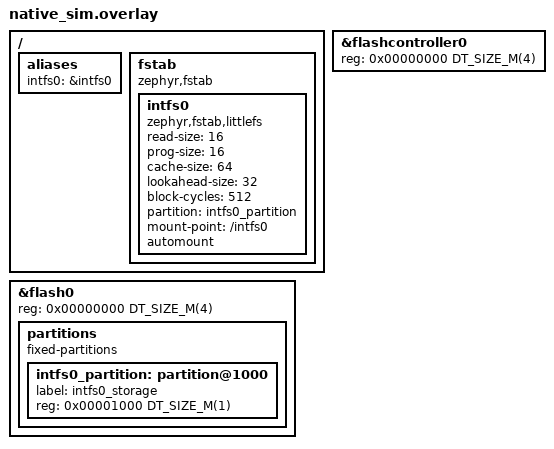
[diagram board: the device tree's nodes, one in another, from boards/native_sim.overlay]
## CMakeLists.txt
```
cmake_minimum_required(VERSION 3.20.0)

set(RT_GAUGE_TEST_SIM_FLASH ON)

# Deliberately NOT RT_GAUGE_TEST_LVGL: UiController goes through UiRendererService,
# which refuses to start without a chosen display, so this suite binds LVGL to the
# dummy display driver (see boards/native_sim.overlay) instead of running headless.
include(${CMAKE_CURRENT_SOURCE_DIR}/../../rt_gauge_test.cmake)

# Use Zephyr's build system
find_package(Zephyr REQUIRED HINTS $ENV{ZEPHYR_BASE})
project(functional_controllers)

include_directories(${APP_SRC_DIR})

set(APP_SRC_CONFIGURATION_DIR ${APP_SRC_DIR}/configuration)
file(GLOB_RECURSE APP_SRC_CONFIGURATION
  ${APP_SRC_CONFIGURATION_DIR}/*.c
  ${APP_SRC_CONFIGURATION_DIR}/*.cpp
)

set(APP_SRC_UI_DOMAIN_DIR ${APP_SRC_DIR}/domain/ui_domain)
file(GLOB_RECURSE APP_SRC_UI_DOMAIN
  ${APP_SRC_UI_DOMAIN_DIR}/*.c
  ${APP_SRC_UI_DOMAIN_DIR}/*.cpp
)

set(APP_SRC_EVENT_BUS_DIR ${APP_SRC_DIR}/event_bus)
file(GLOB_RECURSE APP_SRC_EVENT_BUS
  ${APP_SRC_EVENT_BUS_DIR}/*.c
  ${APP_SRC_EVENT_BUS_DIR}/*.cpp
)

set(APP_SRC_VIEWS_DIR ${APP_SRC_DIR}/views)
file(GLOB_RECURSE APP_SRC_VIEWS
  ${APP_SRC_VIEWS_DIR}/*.c
  ${APP_SRC_VIEWS_DIR}/*.cpp
)

# Only UiController: the other controllers pull in CAN, BLE and the sensor stack,
# none of which this suite exercises.
file(GLOB_RECURSE APP_SRC_CONTROLLERS
  ${APP_SRC_DIR}/controllers/ui_controller.cpp
)

file(GLOB_RECURSE TEST_SOURCES src/*.c src/*.cpp)

# Add all source files to the app target
target_sources(app PRIVATE
  ${APP_SRC_CONFIGURATION}
  ${APP_SRC_CONTROLLERS}
  ${APP_SRC_EVENT_BUS}
  ${APP_SRC_UI_DOMAIN}
  ${APP_SRC_VIEWS}
  ${TEST_SOURCES}
)
```

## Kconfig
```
menu "Zephyr"
source "Kconfig.zephyr"
endmenu

config EERIE_LEAP_HW_VERSION_MAJOR
	int "Hardware version major"
	range 0 255
	default 0

config EERIE_LEAP_HW_VERSION_MINOR
	int "Hardware version minor"
	range 0 255
	default 0

config EERIE_LEAP_HW_VERSION_PATCH
	int "Hardware version patch"
	range 0 65535
	default 0

config EERIE_LEAP_SW_VERSION_MAJOR
	int "Software version major"
	range 0 255
	default 0

config EERIE_LEAP_SW_VERSION_MINOR
	int "Software version minor"
	range 0 255
	default 0

config EERIE_LEAP_SW_VERSION_PATCH
	int "Software version patch"
	range 0 65535
	default 0

config EERIE_LEAP_UI_RENDERER_THREAD_STACK_SIZE
	int "UI renderer thread stack size"
	default 8192

config EERIE_LEAP_FS_SD_THREAD_STACK_SIZE
	int "SD thread stack size"
	default 2048

config EERIE_LEAP_SD_CHECK_INTERVAL_MS
	int "SD check interval ms"
	default 1000
```

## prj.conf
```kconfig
CONFIG_ZTEST=y

#HW Version
CONFIG_EERIE_LEAP_HW_VERSION_MAJOR=2
CONFIG_EERIE_LEAP_HW_VERSION_MINOR=9
CONFIG_EERIE_LEAP_HW_VERSION_PATCH=6

#SW Version
CONFIG_EERIE_LEAP_SW_VERSION_MAJOR=7
CONFIG_EERIE_LEAP_SW_VERSION_MINOR=8
CONFIG_EERIE_LEAP_SW_VERSION_PATCH=4

# Language and Compiler
CONFIG_CPP=y
CONFIG_PICOLIBC=y
CONFIG_STD_CPP23=y
CONFIG_REQUIRES_FULL_LIBCPP=y
CONFIG_CPP_EXCEPTIONS=y
CONFIG_CPP_RTTI=y

# Memory
# Without CONFIG_SHARED_MULTI_HEAP the external PMR falls back to k_malloc, and the
# demo image assets alone are ~870 KB of statically initialised pmr vectors.
# A "small only" sys_heap is capped at 256 KB and fails to init before logging is
# up, so the size mode has to be widened along with the pool.
CONFIG_SYS_HEAP_AUTO=y
CONFIG_HEAP_MEM_POOL_SIZE=4194304

# The controller and its work queues allocate their stacks at runtime.
CONFIG_THREAD_STACK_INFO=y
CONFIG_DYNAMIC_THREAD=y
CONFIG_DYNAMIC_THREAD_ALLOC=y

# C++ exception unwinding needs considerably more stack than the ztest defaults.
CONFIG_MAIN_STACK_SIZE=16384
CONFIG_ZTEST_STACK_SIZE=16384

# Logging And Debugging
CONFIG_LOG=y
# A fault during static init or LVGL setup loses deferred output.
CONFIG_LOG_MODE_IMMEDIATE=y
CONFIG_TEST_RANDOM_GENERATOR=y
CONFIG_THREAD_ANALYZER=y
CONFIG_THREAD_ANALYZER_USE_LOG=y
CONFIG_THREAD_RUNTIME_STATS=y
CONFIG_THREAD_NAME=y
CONFIG_SYS_HEAP_RUNTIME_STATS=y
CONFIG_THREAD_ANALYZER_ISR_STACK_USAGE=n

# FS Config
CONFIG_FLASH=y
CONFIG_FLASH_MAP=y
CONFIG_FILE_SYSTEM=y
CONFIG_FILE_SYSTEM_LITTLEFS=y
CONFIG_FILE_SYSTEM_MKFS=y

# CBOR
CONFIG_ZCBOR=y

# LVGL
# UiRendererService refuses to start without a chosen, ready display, so unlike the
# other LVGL suites this one lets LVGL auto-init against the dummy display driver.
CONFIG_DISPLAY=y
CONFIG_LVGL=y
CONFIG_LV_Z_MEM_POOL_SIZE=1048576
CONFIG_LV_USE_LOG=n
CONFIG_LV_USE_LABEL=y
CONFIG_LV_USE_IMAGE=y
CONFIG_LV_USE_FONT_COMPRESSED=y
CONFIG_LV_FONT_MONTSERRAT_20=y
CONFIG_LV_FONT_DEFAULT_UNSCII_16=y
# The demo assets are AL88, as on the device.
CONFIG_LV_COLOR_DEPTH_8=y
CONFIG_LV_Z_BITS_PER_PIXEL=8

CONFIG_CRC=y
CONFIG_TIMING_FUNCTIONS=y

CONFIG_EERIE_LEAP_RT_CORE=y
CONFIG_EERIE_LEAP_ASSETS=y
CONFIG_EERIE_LEAP_CONFIGURATION=y
CONFIG_EERIE_LEAP_DEVICE_TREE=y
CONFIG_EERIE_LEAP_EVENT_BUS=y
CONFIG_EERIE_LEAP_FS=y
CONFIG_EERIE_LEAP_RANDOM=y
CONFIG_EERIE_LEAP_TIME=y
CONFIG_EERIE_LEAP_LUA_SCRIPT=y
CONFIG_EERIE_LEAP_MATH_PARSER=y
```

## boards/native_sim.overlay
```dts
/ {
	aliases {
		intfs0 = &intfs0;
	};

	fstab {
		compatible = "zephyr,fstab";
		intfs0: intfs0 {
			compatible = "zephyr,fstab,littlefs";
			read-size = <16>;
			prog-size = <16>;
			cache-size = <64>;
			lookahead-size = <32>;
			block-cycles = <512>;
			partition = <&intfs0_partition>;
			mount-point = "/intfs0";
			automount;
		};
	};
};

&flashcontroller0 {
	reg = <0x00000000 DT_SIZE_M(4)>;  // 4MB flash controller
};

// HEX Flash dump can be found in the duild/flash.bin file
&flash0 {
	reg = <0x00000000 DT_SIZE_M(4)>;  // 4MB total flash

	partitions {
		compatible = "fixed-partitions";
		#address-cells = <1>;
		#size-cells = <1>;

		intfs0_partition: partition@1000 {
			label = "intfs0_storage";
			reg = <0x00001000 DT_SIZE_M(1)>;  // 0x00001000 offset, 1MB size
		};
	};
};
```

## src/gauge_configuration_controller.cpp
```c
#include <memory>
#include <zephyr/kernel.h>
#include <zephyr/ztest.h>

#include "configuration/gauge_config/gauge_config.h"
#include "configuration/services/configuration_service.h"

#include "domain/ui_domain/configuration/ui_configuration_manager.h"
#include "domain/ui_domain/models/widget_property.h"

#include "subsys/device_tree/dt_fs.h"
#include "subsys/fs/services/fs_service.h"

#include "views/widgets/indicators/horizontal_chart_indicator/horizontal_chart_indicator.h"

using namespace eerie_leap::configuration::services;
using namespace eerie_leap::subsys::device_tree;
using namespace eerie_leap::subsys::fs::services;
using namespace eerie_leap::domain::ui_domain::configuration;
using namespace eerie_leap::domain::ui_domain::models;
using namespace eerie_leap::views::widgets::indicators;

ZTEST_SUITE(ui_configuration_manager, NULL, NULL, NULL, NULL, NULL);

std::shared_ptr<UiConfiguration> ui_configuration_manager_test_SetupTestGaugeConfig() {
    auto ui_configuration = make_shared_ext<UiConfiguration>();
    ui_configuration->active_screen_index = 8;

    ScreenConfiguration screen_configuration {
        .id = 8,
        .grid = GridSettings {
            .snap_enabled = true,
            .width = 3,
            .height = 3,
            .spacing_px = 0
        },
        .widget_configurations = {
            WidgetConfiguration {
                .type = WidgetType::IndicatorArcFill,
                .id = 0,
                .position_grid = WidgetPosition {
                    .x = 0,
                    .y = 0
                },
                .size_grid = WidgetSize {
                    .width = 3,
                    .height = 3
                },
                .properties = {
                    { WidgetProperty::GetTypeName(WidgetPropertyType::MIN_VALUE), 0 },
                    { WidgetProperty::GetTypeName(WidgetPropertyType::MAX_VALUE), 100 },
                    { WidgetProperty::GetTypeName(WidgetPropertyType::SENSOR_ID), "2348664336" }
                }
            },
            WidgetConfiguration {
                .type = WidgetType::IndicatorDigital,
                .id = 1,
                .position_grid = WidgetPosition {
                    .x = 1,
                    .y = 1
                },
                .size_grid = WidgetSize {
                    .width = 1,
                    .height = 1
                },
                .properties = {
                    { WidgetProperty::GetTypeName(WidgetPropertyType::MIN_VALUE), 0 },
                    { WidgetProperty::GetTypeName(WidgetPropertyType::MAX_VALUE), 100 },
                    { WidgetProperty::GetTypeName(WidgetPropertyType::SENSOR_ID), "2348664336" }
                }
            },
            WidgetConfiguration {
                .type = WidgetType::IndicatorHorizontalChart,
                .id = 2,
                .position_grid = WidgetPosition {
                    .x = 0,
                    .y = 0
                },
                .size_grid = WidgetSize {
                    .width = 3,
                    .height = 1
                },
                .properties = {
                    { WidgetProperty::GetTypeName(WidgetPropertyType::MIN_VALUE), 0 },
                    { WidgetProperty::GetTypeName(WidgetPropertyType::MAX_VALUE), 100 },
                    { WidgetProperty::GetTypeName(WidgetPropertyType::SENSOR_ID), "2348664336" },
                    { WidgetProperty::GetTypeName(WidgetPropertyType::CHART_POINT_COUNT), 35 },
                    { WidgetProperty::GetTypeName(WidgetPropertyType::CHART_TYPE), static_cast<std::uint16_t>(HorizontalChartIndicatorType::LINE) }
                }
            }
        }
    };

    ui_configuration->screen_configurations.push_back(screen_configuration);

    return ui_configuration;
}

ZTEST(ui_configuration_manager, test_UiConfigurationManager_Save_config_successfully_saved) {
    DtFs::InitInternalFs();
    auto fs_service = std::make_shared<FsService>(DtFs::GetInternalFsMp().value());

    fs_service->Format();

    auto ui_configuration_service = std::make_shared<ConfigurationService<GaugeConfig>>("gauge_config", fs_service);
    auto ui_configuration_manager = std::make_shared<UiConfigurationManager>(ui_configuration_service);

    auto gauge_config = ui_configuration_manager_test_SetupTestGaugeConfig();
    bool result = ui_configuration_manager->Update(gauge_config);
    zassert_true(result);
}

ZTEST(ui_configuration_manager, test_UiConfigurationManager_Save_config_and_Load) {
    DtFs::InitInternalFs();
    auto fs_service = std::make_shared<FsService>(DtFs::GetInternalFsMp().value());

    fs_service->Format();

    auto ui_configuration_service = std::make_shared<ConfigurationService<GaugeConfig>>("gauge_config", fs_service);
    auto ui_configuration_manager = std::make_shared<UiConfigurationManager>(ui_configuration_service);

    auto gauge_config = ui_configuration_manager_test_SetupTestGaugeConfig();
    bool result = ui_configuration_manager->Update(gauge_config);
    zassert_true(result);

    auto saved_ui_configuration = *ui_configuration_manager->Get(true);

    zassert_equal(saved_ui_configuration.active_screen_index, gauge_config->active_screen_index);

    for (std::size_t i = 0; i < gauge_config->screen_configurations.size(); i++) {
        zassert_equal(saved_ui_configuration.screen_configurations[i].id, gauge_config->screen_configurations[i].id);
        zassert_equal(saved_ui_configuration.screen_configurations[i].grid.snap_enabled, gauge_config->screen_configurations[i].grid.snap_enabled);
        zassert_equal(saved_ui_configuration.screen_configurations[i].grid.width, gauge_config->screen_configurations[i].grid.width);
        zassert_equal(saved_ui_configuration.screen_configurations[i].grid.height, gauge_config->screen_configurations[i].grid.height);
        zassert_equal(saved_ui_configuration.screen_configurations[i].grid.spacing_px, gauge_config->screen_configurations[i].grid.spacing_px);

        for (std::size_t j = 0; j < gauge_config->screen_configurations[i].widget_configurations.size(); j++) {
            zassert_equal(saved_ui_configuration.screen_configurations[i].widget_configurations[j].type, gauge_config->screen_configurations[i].widget_configurations[j].type);
            zassert_equal(saved_ui_configuration.screen_configurations[i].widget_configurations[j].id, gauge_config->screen_configurations[i].widget_configurations[j].id);
            zassert_equal(saved_ui_configuration.screen_configurations[i].widget_configurations[j].position_grid.x, gauge_config->screen_configurations[i].widget_configurations[j].position_grid.x);
            zassert_equal(saved_ui_configuration.screen_configurations[i].widget_configurations[j].position_grid.y, gauge_config->screen_configurations[i].widget_configurations[j].position_grid.y);
            zassert_equal(saved_ui_configuration.screen_configurations[i].widget_configurations[j].size_grid.width, gauge_config->screen_configurations[i].widget_configurations[j].size_grid.width);
            zassert_equal(saved_ui_configuration.screen_configurations[i].widget_configurations[i].size_grid.height, gauge_config->screen_configurations[i].widget_configurations[i].size_grid.height);
            zassert_equal(saved_ui_configuration.screen_configurations[i].widget_configurations[i].properties.size(), gauge_config->screen_configurations[i].widget_configurations[i].properties.size());

            for (auto& property : gauge_config->screen_configurations[i].widget_configurations[j].properties) {
                zassert_true(saved_ui_configuration.screen_configurations[i].widget_configurations[j].properties[property.first] == gauge_config->screen_configurations[i].widget_configurations[j].properties[property.first]);
            }
        }
    }
}
```

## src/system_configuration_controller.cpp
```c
#include <memory>
#include <zephyr/kernel.h>
#include <zephyr/ztest.h>

#include "configuration/cbor/cbor_system_config/cbor_system_config.h"
#include "configuration/services/cbor_configuration_service.h"
#include "domain/system_domain/configuration/system_configuration_manager.h"

#include "subsys/device_tree/dt_fs.h"
#include "subsys/fs/services/fs_service.h"

using namespace eerie_leap::configuration::services;
using namespace eerie_leap::subsys::device_tree;
using namespace eerie_leap::subsys::fs::services;
using namespace eerie_leap::domain::system_domain::configuration;

ZTEST_SUITE(system_configuration_manager, NULL, NULL, NULL, NULL, NULL);

ZTEST(system_configuration_manager, test_CborSystemConfigurationManager_Save_config_successfully_saved) {
    DtFs::InitInternalFs();
    auto fs_service = std::make_shared<FsService>(DtFs::GetInternalFsMp().value());

    fs_service->Format();

    auto system_configuration_service = std::make_unique<CborConfigurationService<CborSystemConfig>>("system_config", fs_service);
    auto system_configuration_manager = std::make_shared<SystemConfigurationManager>(std::move(system_configuration_service));

    SystemConfiguration system_configuration {
        .hw_version = 23456,
        .sw_version = 87654
    };

    bool result = system_configuration_manager->Update(system_configuration);
    zassert_true(result);

    auto saved_system_configuration = *system_configuration_manager->Get(true);

    zassert_equal(saved_system_configuration.hw_version, system_configuration.hw_version);
    zassert_equal(saved_system_configuration.sw_version, system_configuration.sw_version);
}

ZTEST(system_configuration_manager, test_CborSystemConfigurationManager_Save_config_and_Load) {
    DtFs::InitInternalFs();
    auto fs_service = std::make_shared<FsService>(DtFs::GetInternalFsMp().value());

    fs_service->Format();

    auto system_configuration_service = std::make_unique<CborConfigurationService<CborSystemConfig>>("system_config", fs_service);
    auto system_configuration_manager = std::make_shared<SystemConfigurationManager>(std::move(system_configuration_service));

    SystemConfiguration system_configuration {
        .device_id = 14
    };

    bool result = system_configuration_manager->Update(system_configuration);
    zassert_true(result);

    system_configuration_service = std::make_unique<CborConfigurationService<CborSystemConfig>>("system_config", fs_service);
    system_configuration_manager = std::make_shared<SystemConfigurationManager>(std::move(system_configuration_service));

    auto saved_system_configuration = *system_configuration_manager->Get(true);

    zassert_equal(saved_system_configuration.device_id, system_configuration.device_id);
    zassert_equal(saved_system_configuration.hw_version, 0x02090006);
    zassert_equal(saved_system_configuration.sw_version, 0x07080004);
}
```

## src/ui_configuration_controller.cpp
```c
#include <memory>
#include <zephyr/kernel.h>
#include <zephyr/ztest.h>
#include <eerie_memory.hpp>

#include "configuration/cbor/cbor_ui_config/cbor_ui_config.h"
#include "configuration/services/cbor_configuration_service.h"

#include "domain/ui_domain/configuration/ui_configuration_manager.h"
#include "domain/ui_domain/models/widget_property.h"

#include "subsys/device_tree/dt_fs.h"
#include "subsys/fs/services/fs_service.h"

#include "views/widgets/indicators/horizontal_chart_indicator/horizontal_chart_indicator.h"

using namespace eerie_memory;
using namespace eerie_leap::configuration::services;
using namespace eerie_leap::subsys::device_tree;
using namespace eerie_leap::subsys::fs::services;
using namespace eerie_leap::domain::ui_domain::configuration;
using namespace eerie_leap::domain::ui_domain::models;
using namespace eerie_leap::views::widgets::indicators;

ZTEST_SUITE(ui_configuration_manager, NULL, NULL, NULL, NULL, NULL);

std::shared_ptr<UiConfiguration> ui_configuration_manager_test_SetupTestUiConfiguration() {
    auto ui_configuration = make_shared_pmr<UiConfiguration>(Mrm::GetDefaultPmr());
    ui_configuration->active_screen_group_id = 3;

    auto screen_configuration = make_shared_pmr<ScreenConfiguration>(Mrm::GetDefaultPmr());
    screen_configuration->id = 8;
    screen_configuration->group_id = 3;
    screen_configuration->type = ScreenType::Gauge;
    screen_configuration->z_index = -2;
    screen_configuration->is_visible = true;

    screen_configuration->grid.snap_enabled = true;
    screen_configuration->grid.width = 3;
    screen_configuration->grid.height = 3;
    screen_configuration->grid.spacing_px = 0;

    // First widget
    auto widget1 = make_shared_pmr<WidgetConfiguration>(Mrm::GetDefaultPmr());
    widget1->type = WidgetType::IndicatorArcFill;
    widget1->id = 0;
    widget1->position_grid.x = 0;
    widget1->position_grid.y = 0;
    widget1->size_grid.width = 3;
    widget1->size_grid.height = 3;
    widget1->z_index = -1;
    widget1->properties[WidgetProperty::GetTypeName(WidgetPropertyType::MIN_VALUE)] = 0;
    widget1->properties[WidgetProperty::GetTypeName(WidgetPropertyType::MAX_VALUE)] = 100;
    widget1->properties[WidgetProperty::GetTypeName(WidgetPropertyType::SENSOR_ID)] = "2348664336";
    screen_configuration->AddWidget(std::move(widget1));

    // Second widget
    auto widget2 = make_shared_pmr<WidgetConfiguration>(Mrm::GetDefaultPmr());
    widget2->type = WidgetType::IndicatorDigital;
    widget2->id = 1;
    widget2->position_grid.x = 1;
    widget2->position_grid.y = 1;
    widget2->size_grid.width = 1;
    widget2->size_grid.height = 1;
    widget2->is_visible = false;
    widget2->properties[WidgetProperty::GetTypeName(WidgetPropertyType::MIN_VALUE)] = 0;
    widget2->properties[WidgetProperty::GetTypeName(WidgetPropertyType::MAX_VALUE)] = 100;
    widget2->properties[WidgetProperty::GetTypeName(WidgetPropertyType::SENSOR_ID)] = "2348664336";
    screen_configuration->AddWidget(std::move(widget2));

    // Third widget
    auto widget3 = make_shared_pmr<WidgetConfiguration>(Mrm::GetDefaultPmr());
    widget3->type = WidgetType::IndicatorHorizontalChart;
    widget3->id = 2;
    widget3->position_grid.x = 0;
    widget3->position_grid.y = 0;
    widget3->size_grid.width = 3;
    widget3->size_grid.height = 1;
    widget3->z_index = 2;
    widget3->properties[WidgetProperty::GetTypeName(WidgetPropertyType::MIN_VALUE)] = 0;
    widget3->properties[WidgetProperty::GetTypeName(WidgetPropertyType::MAX_VALUE)] = 100;
    widget3->properties[WidgetProperty::GetTypeName(WidgetPropertyType::SENSOR_ID)] = "2348664336";
    widget3->properties[WidgetProperty::GetTypeName(WidgetPropertyType::CHART_POINT_COUNT)] = 35;
    widget3->properties[WidgetProperty::GetTypeName(WidgetPropertyType::CHART_TYPE)] = static_cast<std::uint16_t>(HorizontalChartIndicatorType::Line);
    screen_configuration->AddWidget(std::move(widget3));

    ui_configuration->screen_configurations.push_back(std::move(screen_configuration));

    return ui_configuration;
}

ZTEST(ui_configuration_manager, test_UiConfigurationManager_Save_config_successfully_saved) {
    DtFs::InitInternalFs();
    auto fs_service = std::make_shared<FsService>(DtFs::GetInternalFsMp());

    fs_service->Format();

    auto cbor_ui_configuration_service = std::make_unique<CborConfigurationService<CborUiConfig>>("ui_config", fs_service);
    auto ui_configuration_manager = std::make_shared<UiConfigurationManager>(
        std::move(cbor_ui_configuration_service));

    auto ui_configuration = ui_configuration_manager_test_SetupTestUiConfiguration();
    bool result = ui_configuration_manager->Update(*ui_configuration);
    zassert_true(result);
}

ZTEST(ui_configuration_manager, test_UiConfigurationManager_Save_config_and_Load) {
    DtFs::InitInternalFs();
    auto fs_service = std::make_shared<FsService>(DtFs::GetInternalFsMp());

    fs_service->Format();

    auto cbor_ui_configuration_service = std::make_unique<CborConfigurationService<CborUiConfig>>("ui_config", fs_service);
    auto ui_configuration_manager = std::make_shared<UiConfigurationManager>(
        std::move(cbor_ui_configuration_service));

    auto ui_configuration = ui_configuration_manager_test_SetupTestUiConfiguration();
    bool result = ui_configuration_manager->Update(*ui_configuration);
    zassert_true(result);

    auto saved_ui_configuration = ui_configuration_manager->Get(true);

    zassert_equal(saved_ui_configuration->active_screen_group_id, ui_configuration->active_screen_group_id);

    for(std::size_t i = 0; i < ui_configuration->screen_configurations.size(); i++) {
        zassert_equal(saved_ui_configuration->screen_configurations[i]->id, ui_configuration->screen_configurations[i]->id);
        zassert_equal(saved_ui_configuration->screen_configurations[i]->group_id, ui_configuration->screen_configurations[i]->group_id);
        zassert_equal(saved_ui_configuration->screen_configurations[i]->type, ui_configuration->screen_configurations[i]->type);
        zassert_equal(saved_ui_configuration->screen_configurations[i]->z_index, ui_configuration->screen_configurations[i]->z_index);
        zassert_equal(saved_ui_configuration->screen_configurations[i]->is_visible, ui_configuration->screen_configurations[i]->is_visible);
        zassert_equal(saved_ui_configuration->screen_configurations[i]->grid.snap_enabled, ui_configuration->screen_configurations[i]->grid.snap_enabled);
        zassert_equal(saved_ui_configuration->screen_configurations[i]->grid.width, ui_configuration->screen_configurations[i]->grid.width);
        zassert_equal(saved_ui_configuration->screen_configurations[i]->grid.height, ui_configuration->screen_configurations[i]->grid.height);
        zassert_equal(saved_ui_configuration->screen_configurations[i]->grid.spacing_px, ui_configuration->screen_configurations[i]->grid.spacing_px);

        for(std::size_t j = 0; j < ui_configuration->screen_configurations[i]->widget_configurations.size(); j++) {
            zassert_equal(saved_ui_configuration->screen_configurations[i]->widget_configurations[j]->type, ui_configuration->screen_configurations[i]->widget_configurations[j]->type);
            zassert_equal(saved_ui_configuration->screen_configurations[i]->widget_configurations[j]->id, ui_configuration->screen_configurations[i]->widget_configurations[j]->id);
            zassert_equal(saved_ui_configuration->screen_configurations[i]->widget_configurations[j]->position_grid.x, ui_configuration->screen_configurations[i]->widget_configurations[j]->position_grid.x);
            zassert_equal(saved_ui_configuration->screen_configurations[i]->widget_configurations[j]->position_grid.y, ui_configuration->screen_configurations[i]->widget_configurations[j]->position_grid.y);
            zassert_equal(saved_ui_configuration->screen_configurations[i]->widget_configurations[j]->size_grid.width, ui_configuration->screen_configurations[i]->widget_configurations[j]->size_grid.width);
            zassert_equal(saved_ui_configuration->screen_configurations[i]->widget_configurations[j]->size_grid.height, ui_configuration->screen_configurations[i]->widget_configurations[j]->size_grid.height);
            zassert_equal(saved_ui_configuration->screen_configurations[i]->widget_configurations[j]->z_index, ui_configuration->screen_configurations[i]->widget_configurations[j]->z_index);
            zassert_equal(saved_ui_configuration->screen_configurations[i]->widget_configurations[j]->is_visible, ui_configuration->screen_configurations[i]->widget_configurations[j]->is_visible);
            zassert_equal(saved_ui_configuration->screen_configurations[i]->widget_configurations[j]->properties.size(), ui_configuration->screen_configurations[i]->widget_configurations[j]->properties.size());
            for(auto& property : ui_configuration->screen_configurations[i]->widget_configurations[j]->properties) {
                zassert_true(saved_ui_configuration->screen_configurations[i]->widget_configurations[j]->properties[property.first] == ui_configuration->screen_configurations[i]->widget_configurations[j]->properties[property.first]);
            }
        }
    }
}
```

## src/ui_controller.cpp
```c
#include <cstdint>
#include <memory>

#include <zephyr/kernel.h>
#include <zephyr/ztest.h>

#include "subsys/device_tree/dt_display.h"
#include "subsys/device_tree/dt_fs.h"
#include "subsys/event_bus/event_bus.h"
#include "subsys/fs/services/fs_service.h"
#include "subsys/threading/work_queue_thread.h"

#include "domain/settings_domain/event_bus/settings_event_type.h"
#include "domain/settings_domain/event_bus/settings_events_channel.h"
#include "domain/ui_domain/event_bus/navigation_event_channel.h"
#include "domain/ui_domain/services/navigation_service.h"

#include "controllers/ui_controller.h"

using eerie_leap::controllers::UiController;
using eerie_leap::domain::settings_domain::event_bus::SettingsEventsChannel;
using eerie_leap::domain::settings_domain::event_bus::SettingsEventType;
using eerie_leap::domain::ui_domain::event_bus::NavigationEventChannel;
using eerie_leap::domain::ui_domain::services::NavigationService;
using eerie_leap::subsys::device_tree::DtDisplay;
using eerie_leap::subsys::device_tree::DtFs;
using eerie_leap::subsys::event_bus::AnySubscription;
using eerie_leap::subsys::event_bus::CreateScopedSubscription;
using eerie_leap::subsys::event_bus::EventBus;
using eerie_leap::subsys::fs::services::FsService;
using eerie_leap::subsys::threading::WorkQueueThread;

namespace {

constexpr int BUS_STACK_SIZE = 4096;
constexpr int CONFIG_WORK_QUEUE_STACK_SIZE = 8192;
constexpr int CONFIG_WORK_QUEUE_PRIORITY = 10;

// The demo configuration UiController installs on every Initialize().
constexpr uint32_t DEMO_OVERLAY_SCREEN_ID = 3;
constexpr uint32_t UNKNOWN_SCREEN_ID = 99;
constexpr uint32_t FIRST_GROUP_ID = 0;

// A navigation change is applied on the bus worker; give it room to run and, for
// the reconcile paths, to publish the follow-up close and apply that too.
constexpr int SETTLE_MS = 300;
constexpr int DISPATCH_TIMEOUT_MS = 1000;

// UiController subscribes to NavigationEventChannel, which stays inert until a
// bus drains it.
class ControllerBus : public EventBus {
public:
    ControllerBus() : EventBus("ctrl_test_bus", BUS_STACK_SIZE) {
        RegisterChannel(NavigationEventChannel::GetInstance());
        RegisterChannel(SettingsEventsChannel::GetInstance());
    }
};

// One controller for the whole suite: Initialize() builds every screen in the demo
// configuration and writes ~870 KB of assets, and its LVGL objects are process-wide.
struct Fixture {
    std::shared_ptr<WorkQueueThread> config_work_queue;
    std::shared_ptr<UiController> controller;
    std::shared_ptr<NavigationService> navigation_service;
};

Fixture fixture;

void* Setup() {
    static ControllerBus bus;

    // UiRendererService reads the display through DtDisplay, which main() primes.
    DtDisplay::Initialize();

    DtFs::InitInternalFs();
    auto fs_service = std::make_shared<FsService>(DtFs::GetInternalFsMp());
    fs_service->Format();

    fixture.config_work_queue = std::make_shared<WorkQueueThread>(
        "cfg_work_q", CONFIG_WORK_QUEUE_STACK_SIZE, CONFIG_WORK_QUEUE_PRIORITY);
    zassert_true(fixture.config_work_queue->Initialize(), "Expected the config work queue to start.");

    fixture.controller = std::make_shared<UiController>(
        fs_service, fixture.config_work_queue, nullptr, nullptr);

    zassert_equal(fixture.controller->Initialize(), 0, "Expected the UI controller to initialize.");
    zassert_equal(fixture.controller->Start(), 0, "Expected the UI controller to start.");

    fixture.navigation_service = fixture.controller->GetNavigationService();
    zassert_not_null(fixture.navigation_service.get(), "Expected a navigation service.");

    return nullptr;
}

// Overlay and group state are process-wide, so each test starts from the same place
// rather than from wherever the previous one left off.
void Reset(void*) {
    if(fixture.navigation_service->IsOverlayActive())
        fixture.navigation_service->CloseOverlay();

    k_msleep(SETTLE_MS);

    fixture.navigation_service->GoToGroup(FIRST_GROUP_ID);
    k_msleep(SETTLE_MS);
}

// Without this the renderer thread keeps the simulation alive after the report.
void Teardown(void*) {
    fixture.controller.reset();
    fixture.navigation_service.reset();
    fixture.config_work_queue.reset();
}

NavigationService& Navigation() { return *fixture.navigation_service; }

} // namespace

ZTEST_SUITE(ui_controller, NULL, Setup, Reset, Reset, Teardown);

// Configure() reads the stored configuration and must have found usable groups.
ZTEST(ui_controller, test_the_controller_starts_on_a_configured_screen_group) {
    auto active_screen_group_id = Navigation().GetActiveGroupId();

    zassert_true(active_screen_group_id.has_value(), "Expected an active screen group.");
    zassert_equal(*active_screen_group_id, FIRST_GROUP_ID);
    zassert_false(Navigation().IsOverlayActive());
}

// An overlay shares a screen_group_id with a real screen; Configure() must skip it rather
// than render it into that group, and navigation must still be able to move.
ZTEST(ui_controller, test_group_navigation_works_alongside_a_configured_overlay) {
    zassert_equal(Navigation().Next(), 0, "Expected the next group to be reachable.");
    k_msleep(SETTLE_MS);

    auto active_screen_group_id = Navigation().GetActiveGroupId();
    zassert_true(active_screen_group_id.has_value());
    zassert_not_equal(*active_screen_group_id, FIRST_GROUP_ID, "Expected the group to have changed.");

    zassert_equal(Navigation().GoToGroup(FIRST_GROUP_ID), 0);
    k_msleep(SETTLE_MS);
}

// The whole ShowOverlay path: event -> ScreenFactory -> OverlayHost::Push. Any
// failure along it reconciles by closing, so an overlay still active after the
// bus has settled is proof the push succeeded.
ZTEST(ui_controller, test_showing_a_configured_overlay_keeps_it_active) {
    zassert_equal(Navigation().ShowOverlay(DEMO_OVERLAY_SCREEN_ID), 0);
    k_msleep(SETTLE_MS);

    zassert_true(Navigation().IsOverlayActive(), "Expected the overlay to have been pushed.");
}

// An overlay is built long after Configure() broadcast the settings state, so the
// bindings its widgets just resolved have to be seeded again or they keep their defaults.
ZTEST(ui_controller, test_showing_an_overlay_asks_settings_owners_to_republish) {
    k_sem requested;
    k_sem_init(&requested, 0, K_SEM_MAX_LIMIT);

    AnySubscription subscription = CreateScopedSubscription(
        SettingsEventsChannel::GetInstance(),
        SettingsEventType::StateRequested,
        [&requested](const SettingsEventsChannel::EventMessage&) { k_sem_give(&requested); });
    zassert_not_null(subscription.get(), "Expected to subscribe to settings events.");

    zassert_equal(Navigation().ShowOverlay(DEMO_OVERLAY_SCREEN_ID), 0);

    zassert_equal(k_sem_take(&requested, K_MSEC(DISPATCH_TIMEOUT_MS)), 0,
        "Expected the overlay to request the settings state.");
}

ZTEST(ui_controller, test_an_active_overlay_blocks_group_navigation) {
    zassert_equal(Navigation().ShowOverlay(DEMO_OVERLAY_SCREEN_ID), 0);
    k_msleep(SETTLE_MS);

    zassert_equal(Navigation().Next(), -EBUSY);
    zassert_equal(Navigation().Previous(), -EBUSY);
    zassert_equal(Navigation().GoToGroup(FIRST_GROUP_ID), -EBUSY);
    zassert_equal(Navigation().ShowOverlay(DEMO_OVERLAY_SCREEN_ID), -EBUSY);
}

ZTEST(ui_controller, test_closing_an_overlay_restores_group_navigation) {
    zassert_equal(Navigation().ShowOverlay(DEMO_OVERLAY_SCREEN_ID), 0);
    k_msleep(SETTLE_MS);

    zassert_equal(Navigation().CloseOverlay(), 0);
    k_msleep(SETTLE_MS);

    zassert_false(Navigation().IsOverlayActive());
    zassert_equal(Navigation().Next(), 0, "Expected group navigation to work again.");
    k_msleep(SETTLE_MS);
}

// A screen id that is not a configured overlay: the service has already taken the
// optimistic state, so the controller has to hand it back or navigation stays stuck.
ZTEST(ui_controller, test_an_unknown_overlay_id_reconciles_navigation) {
    zassert_equal(Navigation().ShowOverlay(UNKNOWN_SCREEN_ID), 0);
    zassert_true(Navigation().IsOverlayActive(), "Expected the request to be taken optimistically.");

    k_msleep(SETTLE_MS);

    zassert_false(Navigation().IsOverlayActive(), "Expected the failed show to close itself.");
    zassert_equal(Navigation().Next(), 0, "Expected group navigation to be unblocked.");
    k_msleep(SETTLE_MS);
}

// A non-overlay screen must not be showable as one, even though its id exists.
ZTEST(ui_controller, test_a_non_overlay_screen_id_reconciles_navigation) {
    zassert_equal(Navigation().ShowOverlay(FIRST_GROUP_ID), 0);
    k_msleep(SETTLE_MS);

    zassert_false(Navigation().IsOverlayActive(), "Expected a plain screen to be refused as an overlay.");
}

// Nothing to close is reported as such, and navigation stays where it is.
ZTEST(ui_controller, test_closing_with_no_overlay_open_is_refused) {
    zassert_equal(Navigation().CloseOverlay(), -ENOENT);
    k_msleep(SETTLE_MS);

    zassert_false(Navigation().IsOverlayActive());
    zassert_true(Navigation().GetActiveGroupId().has_value());
}
```
